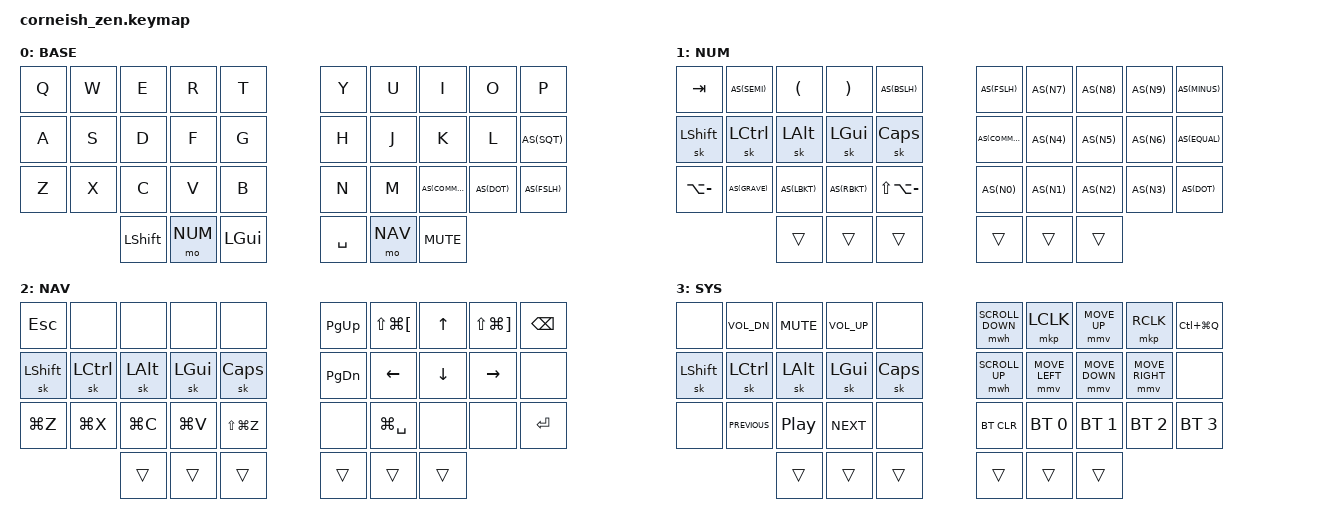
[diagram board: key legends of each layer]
/*
*
* Copyright (c) 2021 Darryl deHaan
* SPDX-License-Identifier: MIT
*
*/

#include <behaviors.dtsi>
#include <dt-bindings/zmk/keys.h>
#include <dt-bindings/zmk/bt.h>
#include <dt-bindings/zmk/mouse.h>

#define BASE	0
#define NUM		1
#define NAV		2
#define SYS		3

#define AS(keycode) &as LS(keycode) keycode

/ {
  chosen {
    //zmk,matrix_transform = &default_transform;
    zmk,matrix_transform = &five_column_transform;
  };
};

/ {
    conditional_layers {
        compatible = "zmk,conditional-layers";
        tri_layer {
            if-layers = <NUM NAV>;
            then-layer = <SYS>;
        };
    };
};

&sk {
    release-after-ms = <2000>;
    quick-release;
};

&mmv {
    time-to-max-speed-ms = <60>;
    delay-ms = <0>;
    acceleration-exponent=<1>;
};

&mwh {
    time-to-max-speed-ms = <60>;
    delay-ms = <0>;
    acceleration-exponent=<1>;
};

/ {
    behaviors {
        as: auto_shift {
            compatible = "zmk,behavior-hold-tap";
            label = "AUTO_SHIFT";
            #binding-cells = <2>;
            tapping_term_ms = <150>;
            quick_tap_ms = <0>;
            flavor = "tap-preferred";
            bindings = <&kp>, <&kp>;
        };
    };

    keymap {
        compatible = "zmk,keymap";
        default_layer {
            label = "BASE";
            bindings = <
            &kp Q &kp W &kp E &kp R &kp T &kp Y &kp U &kp I     &kp O   &kp P
            &kp A &kp S &kp D &kp F &kp G &kp H &kp J &kp K     &kp L   AS(SQT)
            &kp Z &kp X &kp C &kp V &kp B &kp N &kp M AS(COMMA) AS(DOT) AS(FSLH)
            &kp LSHFT &mo NUM &kp LGUI &kp SPACE &mo NAV &kp C_MUTE
            >;
        };
        numpad_layer {
            label = "NUM";
            bindings = <
            &kp TAB AS(SEMI) &kp LPAR &kp RPAR AS(BSLH) AS(FSLH) AS(N7) AS(N8) AS(N9) AS(MINUS)
            &sk LSHFT &sk LCTRL &sk LALT &sk LGUI &sk CAPS AS(COMMA) AS(N4) AS(N5) AS(N6) AS(EQUAL)
            &kp LA(MINUS) AS(GRAVE) AS(LBKT) AS(RBKT) &kp LS(LA(MINUS)) AS(N0) AS(N1) AS(N2) AS(N3) AS(DOT)
            &trans &trans &trans &trans &trans &trans
            >;
        };
        navigation_layer {
            label = "NAV";
            bindings = <
            &kp ESC &none &none &none &none &kp PG_UP &kp LS(LG(LBKT)) &kp UP &kp LS(LG(RBKT)) &kp BSPC
            &sk LSHFT &sk LCTRL &sk LALT &sk LGUI &sk CAPS &kp PG_DN &kp LEFT &kp DOWN &kp RIGHT &none
            &kp LG(Z) &kp LG(X) &kp LG(C) &kp LG(V) &kp LS(LG(Z)) &none &kp LG(SPACE) &none &none &kp RET
            &trans &trans &trans &trans &trans &trans
            >;
        };
        system_layer {
            label = "SYS";
            bindings = <
            &none &kp C_VOL_DN &kp C_MUTE &kp C_VOL_UP &none &mwh SCROLL_DOWN &mkp LCLK &mmv MOVE_UP &mkp RCLK &kp LC(LG(Q))
            &sk LSHFT &sk LCTRL &sk LALT &sk LGUI &sk CAPS &mwh SCROLL_UP &mmv MOVE_LEFT &mmv MOVE_DOWN &mmv MOVE_RIGHT &none
            &none &kp C_PREVIOUS &kp C_PLAY_PAUSE &kp C_NEXT &none &bt BT_CLR &bt BT_SEL 0 &bt BT_SEL 1 &bt BT_SEL 2 &bt BT_SEL 3
            &trans &trans &trans &trans &trans &trans
            >;
        };
    };
};
